# CSI2_PHY register map
Vendor: Texas Instruments
Peripheral module from a debugger description file (folder awr2544).
Registers are 32-bit, access per field, no defined reset value unless marked. A register's access mark holds for its fields unless they carry their own. Offsets are as the file gives them; lines under a group give offsets from that group; [hi:lo] are bit positions; {n}, {i} and the like mark numbered series; 'fields as' and 'values as' point back to an identical list; <NAME> marks a mode.

## CSI2_PHY
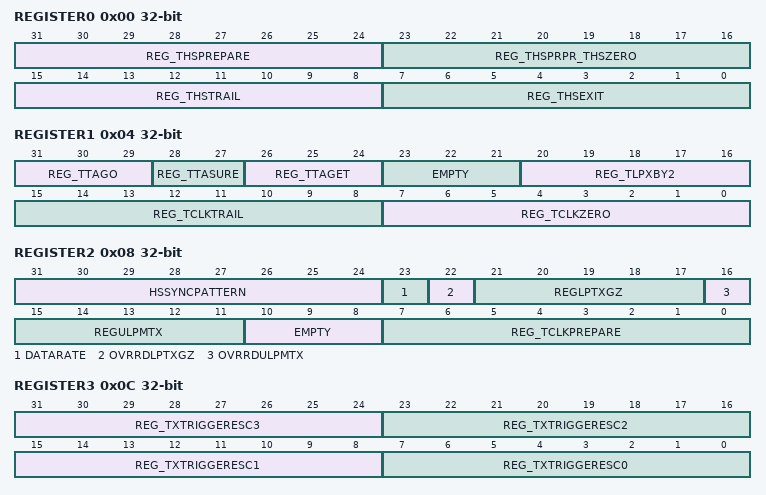
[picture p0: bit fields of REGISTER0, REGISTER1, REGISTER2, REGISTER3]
0x00 REGISTER0 rw — First Register
  [31:24] REG_THSPREPARE — REG_THSPREPARE timing parameter in multiples of DDR clock period. DDR clock = CLKIN4DDR/4. D-PHY spec:40ns+4UI-85ns+6UI Auctual value seen on line : = REG_THSPREPARE timer + analog delay & slew on signals = REG_THSPREPARE +(-26.5ns -- +4 ns ) PROGRAMMED VALUE = ceil( 70 ns / DDR Clock Period) + 2 Default value is programmed for 400 MHz
  [23:16] REG_THSPRPR_THSZERO — REG_THSPREPARE_THSZERO timing parameter in multiples of DDR clock period. DDR clock = CLKIN4DDR/4. D-PHY spec: > 145ns + 10 UI Actual value seen on line N= REG_THSPREPARE_THSZERO - REG_THSPREPARE M=REG_THSPREPARE = [ceil [(N+3)/4] * 4 + ceil [M/4] * 4 + 3] * DDR_Clock_Period+[~-29ns - 0ns] PROGRAMMED VALUE = ceil ( 175 ns/ DDR Clock Period ) + 2 Default value is programmed for 400 MHz
  [15:8] REG_THSTRAIL — REG_THSTRAIL timing parameter in multiples of DDR clock period. DDR clock = CLKIN4DDR/4. D-PHY spec : > 60ns + 4UI Actual value seen on line : N = REG_THSTRAIL = [ceil [(N+3)/4] * 4 - 2.75] * DDR_Clock_period +(~ 0ns - 5ns) PROGRAMMED VALUE = ceil ( 60 ns / DDR Clock Period ) + 5 Default value is programmed for 400 MHz
  [7:0] REG_THSEXIT — REG_THSEXIT timing parameter in multiples of DDR clock frequency. DDR clock = CLKIN4DDR/4. D-PHy spec : > 100 ns Actual value seen on line : N = REG_THSEXIT = THSEXIT timer + analog delay & slew on LP signals = [ceil[N/4] * 4 ] * DDR_CLOCK_PERIOD - (~3 ns - 45 ns ) PROGRAMMED VALUE = ceil ( 145 ns/ DDR Clock Period) Default value is programmed for 400 MHz
0x04 REGISTER1
  [31:29] REG_TTAGO rw — TTA-GO timing in terms of number of TXCLKESC clocks 000 == 2 cycles 001 == 3 cycles 010 == 4 cycles 011 == 5 cycles 100 == 6 cycles 101 == 7 cycles 110 == 8 cycles 111 == 9 cycles Default value: 4 cycles
  [28:27] REG_TTASURE rw — TTA-SURE timing in terms of number of TXCLKESC clocks 00 == 2 cycles 01 == Reserved 10 == 3 cycles 11 == 4 cycles Default value: 2 cycles
  [26:24] REG_TTAGET rw — TTA-GET timing in terms of number of TXCLKESC clocks 000 == 3 cycles 001 == 4 cycles 010 == 5 cycles 011 == 6 cycles 100 == 7 cycles 101 == 8 cycles 110 == 9 cycles 111 == 10 cycles Default value: 5 cycles
  [23:21] EMPTY ro — Reserved
  [20:16] REG_TLPXBY2 rw — (TLPX)/2 timing parameter in multiples of DDR clock frequency. DDR clock = CLKIN4DDR/4. PROGRAMMED VALUE = ceil (25 ns / DDR Clock Period ) Default value is programmed for 400 MHz Note : TLPX is used to define the length of LP-01 state in HS start of Transmision sequences on clock and data lanes. For all other purposes TLPX is defined by the period of TXLPESC
  [15:8] REG_TCLKTRAIL rw — REG_TCLKTRAIL timing parameter in multiples of DDR clock frequency. DDR clock = CLKIN4DDR/4. D-PHY spec : 60 ns PROGRAMMED VALUE = ceil (60 ns / DDR Clock Period) Actual value seen on line: N = REG_TCLKTRAIL = [ceil[(N+3)/4] *4 - 1.5] * DDR_Clock_Period + (~0 ns - 5 ns) PROGRAMMED VALUE = ceil (60 ns / DDR Clock Period ) + 2 Default value is programmed for 400 MHz
  [7:0] REG_TCLKZERO rw — REG_TCLKZERO timing parameter in multiples of DDR clock period. DDR clock = CLKIN4DDR/4. D-PHY spec :[REG_TCLKPREPARE + REG_TCLKZERO] > 300 ns Derived spec for REG_TCLKERO (Min REG_TCLKPREPARE = 38 ns) REG_TCLKZERO > 262 ns Actual value seen on line : N = REG_TCLKZERO M = REG_TCLKPREPARE = [ceil [(N+3)/4] *4 + ceil (M/4) * 4 - M + 2] * DDR_Clock_Period + [~0ns - 5ns] PROGRA MMED VALUE = ceil (265 ns / DDR Clock Period) Default value is programmed for 400 MHz
0x08 REGISTER2 rw
  [31:24] HSSYNCPATTERN — Default : 184 (10111000). MSB (last received bit of sync pattern), LSB (first received bit of sync pattern).
  [23] DATARATE — This bit is set high if data rate < 400Mbps => DDR clock < 200MHz. 1 : Will put High-Speed Transmitters in power-saving mode. Default value : 0
  [22] OVRRDLPTXGZ — 1: Override with register 0: Default
  [21:17] REGLPTXGZ — 1: Tri-stated 0: Not Tri-stated
  [16] OVRRDULPMTX — 1: Override with register 0: Default
  [15:11] REGULPMTX — 1: Transmit ULPM 0: Don't transmit ULPM
  [10:8] EMPTY — Reserved
  [7:0] REG_TCLKPREPARE — D-PHY spec : 38ns - 95 ns Actual value seen online : = REG_TCLKPREPARE timer + analog delay & slew on LP signals = REG_TCLKPREPARE * DDR Clock Period + [~25 ns -+ 5 ns) PROGRAMMED VALUE = ceil (65 ns / DDR Clock Period) Default value is programmed for 400 MHz
0x0C REGISTER3 rw
  [31:24] REG_TXTRIGGERESC3 — Transmitted pattern when REG_TXTRIGGERESC3 is asserted (first bit transmitted to last bit transmitted). Default: 01100010
  [23:16] REG_TXTRIGGERESC2 — Default: 01011101
  [15:8] REG_TXTRIGGERESC1 — Default: 00100001
  [7:0] REG_TXTRIGGERESC0 — Default: 10100000
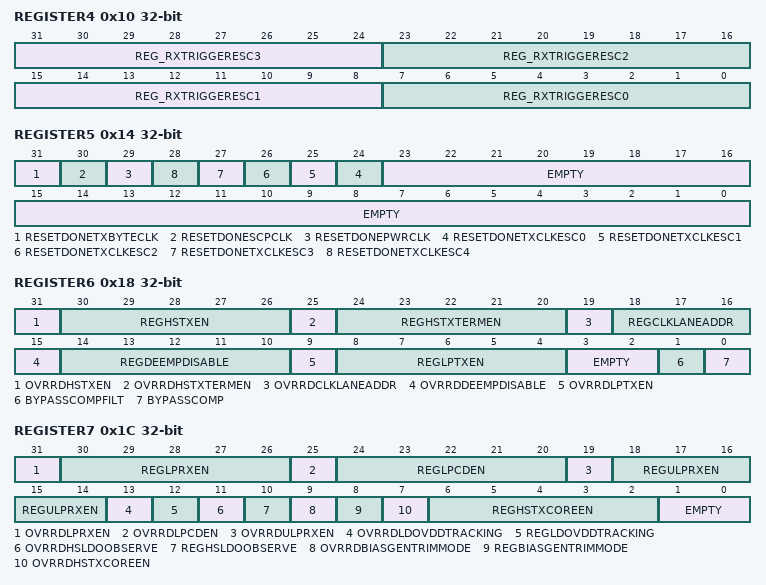
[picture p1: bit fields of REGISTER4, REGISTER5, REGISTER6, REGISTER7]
0x10 REGISTER4 rw
  [31:24] REG_RXTRIGGERESC3 — Received pattern for which REG_RXTRIGGERESC3 is asserted (first bit transmitted to last bit transmitted). Default: 01100010
  [23:16] REG_RXTRIGGERESC2 — Default: 01011101
  [15:8] REG_RXTRIGGERESC1 — Default: 00100001
  [7:0] REG_RXTRIGGERESC0 — Default: 10100000
0x14 REGISTER5 ro
  [31] RESETDONETXBYTECLK
  [30] RESETDONESCPCLK
  [29] RESETDONEPWRCLK
  [n+24] RESETDONETXCLKESC{n} (n=0..4)
  [23:0] EMPTY — Reserved
0x18 REGISTER6
  [31] OVRRDHSTXEN rw — 1: Override with register 0: Default
  [30:26] REGHSTXEN rw — 1: Enable 0: Disable
  [25] OVRRDHSTXTERMEN rw — 1: Override with register 0: Default
  [24:20] REGHSTXTERMEN rw — 1: Enable 0: Disable
  [19] OVRRDCLKLANEADDR rw — 1: Override with register 0: Default
  [18:16] REGCLKLANEADDR rw — 001: Lane0 -> clock lane 010: Lane1-> clock lane 011: Lane2 -> clock lane 101: Lane3 -> clock lane Other states are reserved. Default: 001
  [15] OVRRDDEEMPDISABLE rw — 1: Override with register bit 0: Default
  [14:10] REGDEEMPDISABLE rw — 1:Disable De-emphasis 0:Enable De-emphasis
  [9] OVRRDLPTXEN rw — 1: Override with register 0: Default
  [8:4] REGLPTXEN rw — 1: Enable 0: Disable
  [3:2] EMPTY ro — Reserved
  [1] BYPASSCOMPFILT rw — 1 : Bypass LP-RX and LP-CD with fast buffers 0 : Do not bypass
  [0] BYPASSCOMP rw — 1 : Bypass LP-RX and LP-CD comparator with fast buffers 0 : Do not bypass
0x1C REGISTER7
  [31] OVRRDLPRXEN rw — 1: Override with register 0: Default
  [30:26] REGLPRXEN rw — 1:Enable 0:Disable
  [25] OVRRDLPCDEN rw — 1: Override with register 0: Default
  [24:20] REGLPCDEN rw — 1:Enable 0:Disable
  [19] OVRRDULPRXEN rw — 1: Override with register 0: Default
  [18:14] REGULPRXEN rw — 1:Enable 0:Disable
  [13] OVRRDLDOVDDTRACKING rw — 1: Override with register 0: Default
  [12] REGLDOVDDTRACKING rw — 1: Enable LDO tracking VDD 0: Disable(default)
  [11] OVRRDHSLDOOBSERVE rw — 1: Override with register 0: Default
  [10] REGHSLDOOBSERVE rw — 1: Enable HS LDO observe 0: Disable
  [9] OVRRDBIASGENTRIMMODE rw — 1: Override with register 0: Default
  [8] REGBIASGENTRIMMODE rw — 1: Enable 0: Disable
  [7] OVRRDHSTXCOREEN rw — 1: Override with register 0: Default
  [6:2] REGHSTXCOREEN rw — 1: Enable 0: Disable(default)
  [1:0] EMPTY ro — Reserved
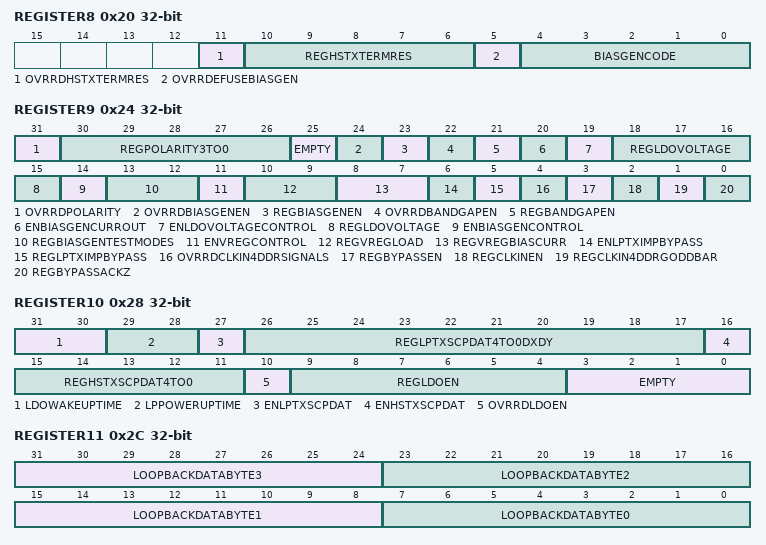
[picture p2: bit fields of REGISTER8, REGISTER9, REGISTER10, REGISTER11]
0x20 REGISTER8
  [11] OVRRDHSTXTERMRES rw — 1: Override EFUSE bits 0: Use EFUSE bits
  [10:6] REGHSTXTERMRES rw — 11111: Max resistance 10000: Nominal resistance 00000: Min resistance
  [5] OVRRDEFUSEBIASGEN rw — 1: Override EFUSE bits 0: Use EFUSE bits
  [4:0] BIASGENCODE rw — 11111: Min current 10000: Nominal current 00000: Max current
0x24 REGISTER9
  [31] OVRRDPOLARITY rw — 1: Override with register bit 0: Default
  [30:26] REGPOLARITY3TO0 rw — 1: DX=DN, DY=DP 0: DX=DP, DY=DN
  [25] EMPTY ro — Reserved
  [24] OVRRDBIASGENEN rw — 1: Override with Register bit 0 : Default
  [23] REGBIASGENEN rw — 1: Enable 0: Disable
  [22] OVRRDBANDGAPEN rw — 1: Override with Register bit 0: Default
  [21] REGBANDGAPEN rw — 1: Enable 0: Disable
  [20] ENBIASGENCURROUT rw — 1: Enable biasgen current (10uA) brought out. 0: Biasgen current is not brought out.(Note this testmode will be used only in testchips. Not expected to be used in SOC)
  [19] ENLDOVOLTAGECONTROL rw — 1: Control LDO output voltage through register bits. 0: Set LDO voltage to default
  [18:15] REGLDOVOLTAGE rw — 1111: Maximum voltage 0000: Minimum voltage Default: 0100
  [14] ENBIASGENCONTROL rw — 1: Control Bias current through register bits. 0: Set bias current to default.
  [13:12] REGBIASGENTESTMODES rw — Default: 00
  [11] ENVREGCONTROL rw — 1: Enable control. 0: Use default current
  [10:9] REGVREGLOAD rw — Default: 00
  [8:7] REGVREGBIASCURR rw — Default: 00
  [6] ENLPTXIMPBYPASS rw — 1: LP-TX bypass controlled by register bit. 0: Default value
  [5] REGLPTXIMPBYPASS rw — 1: output impedance bypassed permanently 0: output impedance not bypassed at all
  [4] OVRRDCLKIN4DDRSIGNALS rw — 1: Override signals with register settings 0: Default
  [3] REGBYPASSEN rw — BYPASSEN
  [2] REGCLKINEN rw — CLKINEN
  [1] REGCLKIN4DDRGODDBAR rw — CLKIN4DDRGOODBAR
  [0] REGBYPASSACKZ rw — BYPASSACKZ
0x28 REGISTER10
  [31:30] LDOWAKEUPTIME rw — Set LPTX wakeup time counter in PWRCLK cycles or TXCLKESC cycles. In PWRCLK cycles (when PWRCMD is changed). 00: 250 (Default) 01: 313 10: 375 11: 500
  [29:28] LPPOWERUPTIME rw — LDO wakeup time counter in number of PWRCLK cycles (approximate) 00: 12500 (Default) 01: 6250 10: 31250 11: 62500
  [27] ENLPTXSCPDAT rw — 1: LPTX Data Taken from register 0: Default
  [26:17] REGLPTXSCPDAT4TO0DXDY rw — 26-17: Data for DX4,DY4,DX3,DY3, DX2,DY2, DX1,DY1, DX0,DY0 respectively
  [16] ENHSTXSCPDAT rw — 1: HS Data Taken from register 0: Default
  [15:11] REGHSTXSCPDAT4TO0 rw — 15-11: Data for D4, D3, D2, D1 and D0 respectively
  [10] OVRRDLDOEN rw — 1: Override with Register bit 0: Default
  [9:4] REGLDOEN rw — 1: Enable 0: Disable
  [3:0] EMPTY ro — Reserved
0x2C REGISTER11 rw
  [31:24] LOOPBACKDATABYTE3 — Fourth byte transmitted in loop-back mode
  [23:16] LOOPBACKDATABYTE2 — Third byte transmitted in loop-back mode
  [15:8] LOOPBACKDATABYTE1 — Second byte transmitted in loop-back mode
  [7:0] LOOPBACKDATABYTE0 — First byte transmitted in loop-back mode
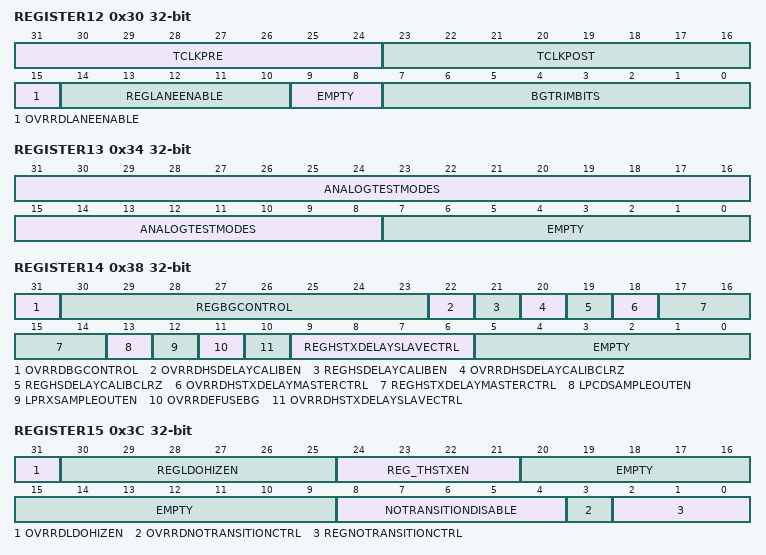
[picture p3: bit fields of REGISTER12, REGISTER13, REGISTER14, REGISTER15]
0x30 REGISTER12
  [31:24] TCLKPRE rw — TCLK-PRE used in loop-back mode - in number of DDR clocksDefault: 4 DDRCLK cycles
  [23:16] TCLKPOST rw — TCLK-POST used in loop-back mode - in number of DDR clocksDefault: 50 DDRCLK cycles
  [15] OVRRDLANEENABLE rw — Default: 0
  [14:10] REGLANEENABLE rw — Default: 00000
  [9:8] EMPTY ro — Reserved
  [7:0] BGTRIMBITS rw — Maximum: 100000 Minimum: 011111 Default: 000000
0x34 REGISTER13
  [31:8] ANALOGTESTMODES rw — Default:0
  [7:0] EMPTY ro — Reserved
0x38 REGISTER14
  [31] OVRRDBGCONTROL rw — 1: Override bandgap control bits with register value 0: Default
  [30:23] REGBGCONTROL rw — Default: 01111100
  [22] OVRRDHSDELAYCALIBEN rw — 1: Override with register bit 0: Default
  [21] REGHSDELAYCALIBEN rw — 1: Enable 0: Disable
  [20] OVRRDHSDELAYCALIBCLRZ rw — 1: Override with register bit 0: Default
  [19] REGHSDELAYCALIBCLRZ rw — 1: Clrz disabled(default) 0. Clrz enable
  [18] OVRRDHSTXDELAYMASTERCTRL rw — 1: Override with register bit 0: Default
  [17:14] REGHSTXDELAYMASTERCTRL rw — Default: 0000
  [13] LPCDSAMPLEOUTEN rw — 1: Enable sampled data to be brought out on WPO pins. 0: Normal mode
  [12] LPRXSAMPLEOUTEN rw — 1: Enable sampled data to be brought out on WPO pins. 0: Normal mode
  [11] OVRRDEFUSEBG rw — 1: Override EFUSE bits 0: Use EFUSE bits
  [10] OVRRDHSTXDELAYSLAVECTRL rw — 1: Override with register bit 0: Default
  [9:6] REGHSTXDELAYSLAVECTRL rw — Default: 0000
  [5:0] EMPTY ro — Reserved
0x3C REGISTER15
  [31] OVRRDLDOHIZEN rw — 1: Override with register bit 0: Default
  [30:25] REGLDOHIZEN rw — 1: LDO in Hiz Mode 0: LDO not in Hiz mode
  [24:21] REG_THSTXEN rw — REG_THSTXEN is timing parameter for HSTXEN deassertion staggering. staggered time = REG_THSTXEN * (4 * Reg_Tlpxby2) Default : 1010 1000 ns 0000 : Reserved
  [20:9] EMPTY ro — Reserved
  [8:4] NOTRANSITIONDISABLE rw — 1: NoTransition disabled 0: NoTransition controlled by FSM Default: 00000
  [3] OVRRDNOTRANSITIONCTRL rw — 1: Override with register bits 0: Default
  [2:0] REGNOTRANSITIONCTRL rw — Default: 011
